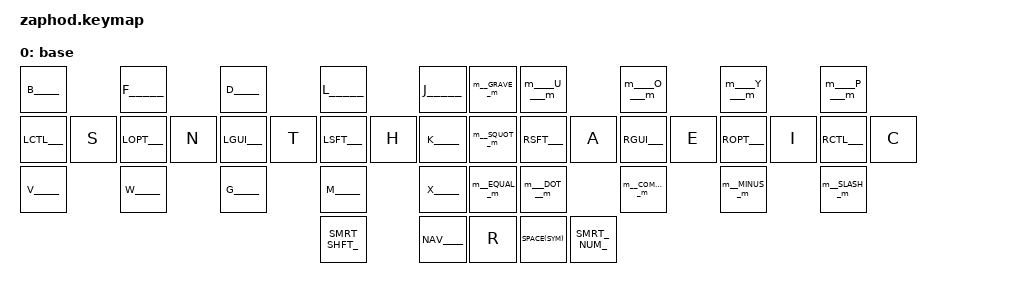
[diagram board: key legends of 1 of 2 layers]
#include "zmk-helpers/key-labels/34.h"

#define MOUSE_IGNORED_KEYS LT1 LT3 RT0 RT1 RT2 RT3 RT4 RM1 RM2 RM3 RB1 RB2 RH0 RH1
#define REVERSE_SWAPPER RH0

/* source the base definitions */
#include "base.dtsi"

// ZMK_CONDITIONAL_LAYER(sys, SYM NUM, SYS)  // FN + NUM --> SYS

ZMK_LAYER(base,
//╭─────────────┬─────────────q─────────────┬─────────────┬─────────────╮ ╭─────────────┬─────────────┬─────────────┬─────────────┬─────────────╮
    _____B_____   _____F_____   _____D_____   _____L_____   _____J_____     m__GRAVE__m   m____U____m   m____O____m   m____Y____m   m____P____m
//├─────────────┼─────────────┼─────────────┼─────────────┼─────────────┤ ├─────────────┼─────────────┼─────────────┼─────────────┼─────────────┤
    __LCTL___ S   __LOPT___ N   __LGUI___ T   __LSFT___ H   _____K_____     m__SQUOT__m   __RSFT___ A   __RGUI___ E   __ROPT___ I   __RCTL___ C
//├─────────────┼─────────────z─────────────┼─────────────┼─────────────┤ ├─────────────┼─────────────┼─────────────┼─────────────┼─────────────┤
    _____V_____   _____W_____   _____G_____   _____M_____   _____X_____     m__EQUAL__m   m___DOT___m   m__COMMA__m   m__MINUS__m   m__SLASH__m 
//╰─────────────┴─────────────┴─────────────┴─────────────┴─────────────┤ ├─────────────┴─────────────┴─────────────┴─────────────┴─────────────╯
                                              _SMRT_SHFT_   __NAV____ R     _SPACE(SYM)   _SMRT__NUM_
//                                          ╰─────────────┴─────────────╯ ╰─────────────┴─────────────╯
)

ZMK_LAYER(nav,
//╭─────────────┬─────────────┬─────────────┬─────────────┬─────────────╮ ╭─────────────┬─────────────┬─────────────┬─────────────┬─────────────╮
    ____ESC____   __TAB_SWP__   __APP_SWP__   __WIN_SWP__   ___________     __PAGE_UP__   _BACKSPACE_   ____UP_____   ___________   ___________
//├─────────────┼─────────────┼─────────────┼─────────────┼─────────────┤ ├─────────────┼─────────────┼─────────────┼─────────────┼─────────────┤
    &sk LCTRL     &sk LALT      &sk LGUI      &sk LSHFT     ___________     _PAGE_DOWN_   ___LEFT____   ___DOWN____   ___RIGHT___   ___ENTER___
//├─────────────┼─────────────┼─────────────┼─────────────┼─────────────┤ ├─────────────┼─────────────┼─────────────┼─────────────┼─────────────┤
    ___________   _UNDO_REDO_   __CPY_CUT__   _PSTE_SLCT_   ___________     ___________   ____TAB____   ___________   ___________   ___________ 
//╰─────────────┴─────────────┴─────────────┴─────────────┴─────────────┤ ├─────────────┴─────────────┴─────────────┴─────────────┴─────────────╯
                                              ___________   vvvvvvvvvvv     ___SHIFT___    CANCEL
//                                          ╰─────────────┴─────────────╯ ╰─────────────┴─────────────╯
)

/*****************************************************************************
    Sample Layer
 *****************************************************************************

ZMK_LAYER(layer_name,
//╭─────────────┬─────────────┬─────────────┬─────────────┬─────────────╮ ╭─────────────┬─────────────┬─────────────┬─────────────┬─────────────╮
    ___________   ___________   ___________   ___________   ___________     ___________   ___________   ___________   ___________   ___________
//├─────────────┼─────────────┼─────────────┼─────────────┼─────────────┤ ├─────────────┼─────────────┼─────────────┼─────────────┼─────────────┤
    ___________   ___________   ___________   ___________   ___________     ___________   ___________   ___________   ___________   ___________
//├─────────────┼─────────────┼─────────────┼─────────────┼─────────────┤ ├─────────────┼─────────────┼─────────────┼─────────────┼─────────────┤
    ___________   ___________   ___________   ___________   ___________     ___________   ___________   ___________   ___________   ___________ 
//╰─────────────┴─────────────┴─────────────┴─────────────┴─────────────┤ ├─────────────┴─────────────┴─────────────┴─────────────┴─────────────╯
                                              ___________   ___________     ___________   ___________
//                                          ╰─────────────┴─────────────╯ ╰─────────────┴─────────────╯
)

******************************************************************************/

/*****************************************************************************
    Colemak Layer
 *****************************************************************************

//╭─────────────┬─────────────┬─────────────┬─────────────┬─────────────╮ ╭─────────────┬─────────────┬─────────────┬─────────────┬─────────────╮
    _____Q_____   _____W_____   _____F_____   _____P_____   _____B_____     _____J_____   _____L_____   _____U_____   _____Y_____   ___SQUOT___ 
//├─────────────┼─────────────┼─────────────┼─────────────┼─────────────┤ ├─────────────┼─────────────┼─────────────┼─────────────┼─────────────┤
    __LCTL__A__   __LOPT__R__   __LGUI__S__   __LSFT__T__   _____G_____     _____M_____   __RSFT__N__   __RGUI__E__   __ROPT__I__   __RCTL__O__
//├─────────────┼─────────────┼─────────────┼─────────────┼─────────────┤ ├─────────────┼─────────────┼─────────────┼─────────────┼─────────────┤
    _____Z_____   _____X_____   _____C_____   _____D_____   _____V_____     _____K_____   _____H_____   m__COMMA__m   m___DOT___m   ___SLASH___ 
//╰─────────────┴─────────────┴─────────────┴─────────────┴─────────────┤ ├─────────────┴─────────────┴─────────────┴─────────────┴─────────────╯
                                              __FUN_RPT__   __SPC_NAV__     _SMRT_SHFT_   _SMRT__NUM_
//                                          ╰─────────────┴─────────────╯ ╰─────────────┴─────────────╯

******************************************************************************/


/*****************************************************************************
    Prometheus Layer
 *****************************************************************************

//╭─────────────┬─────────────q─────────────┬─────────────┬─────────────╮ ╭─────────────┬─────────────┬─────────────┬─────────────┬─────────────╮
    _____B_____   _____F_____   _____D_____   _____L_____   _____J_____     m__GRAVE__m   m____U____m   m____O____m   m____Y____m   m____P____m
//├─────────────┼─────────────┼─────────────┼─────────────┼─────────────┤ ├─────────────┼─────────────┼─────────────┼─────────────┼─────────────┤
    __LCTL__S__   __LOPT__N__   __LGUI__T__   __LSFT__H__   _____K_____     m__SQUOT__m   __RSFT__A__   __RGUI__E__   __ROPT__I__   __RCTL__C__
//├─────────────┼─────────────z─────────────┼─────────────┼─────────────┤ ├─────────────┼─────────────┼─────────────┼─────────────┼─────────────┤
    _____V_____   _____W_____   _____G_____   _____M_____   _____X_____     m__EQUAL__m   m___DOT___m   m__COMMA__m   m__MINUS__m   m__SLASH__m 
//╰─────────────┴─────────────┴─────────────┴─────────────┴─────────────┤ ├─────────────┴─────────────┴─────────────┴─────────────┴─────────────╯
                                              _SMRT_SHFT_   __R___NAV__     __SPC_SYM__   _SMRT__NUM_
//                                          ╰─────────────┴─────────────╯ ╰─────────────┴─────────────╯

******************************************************************************/
